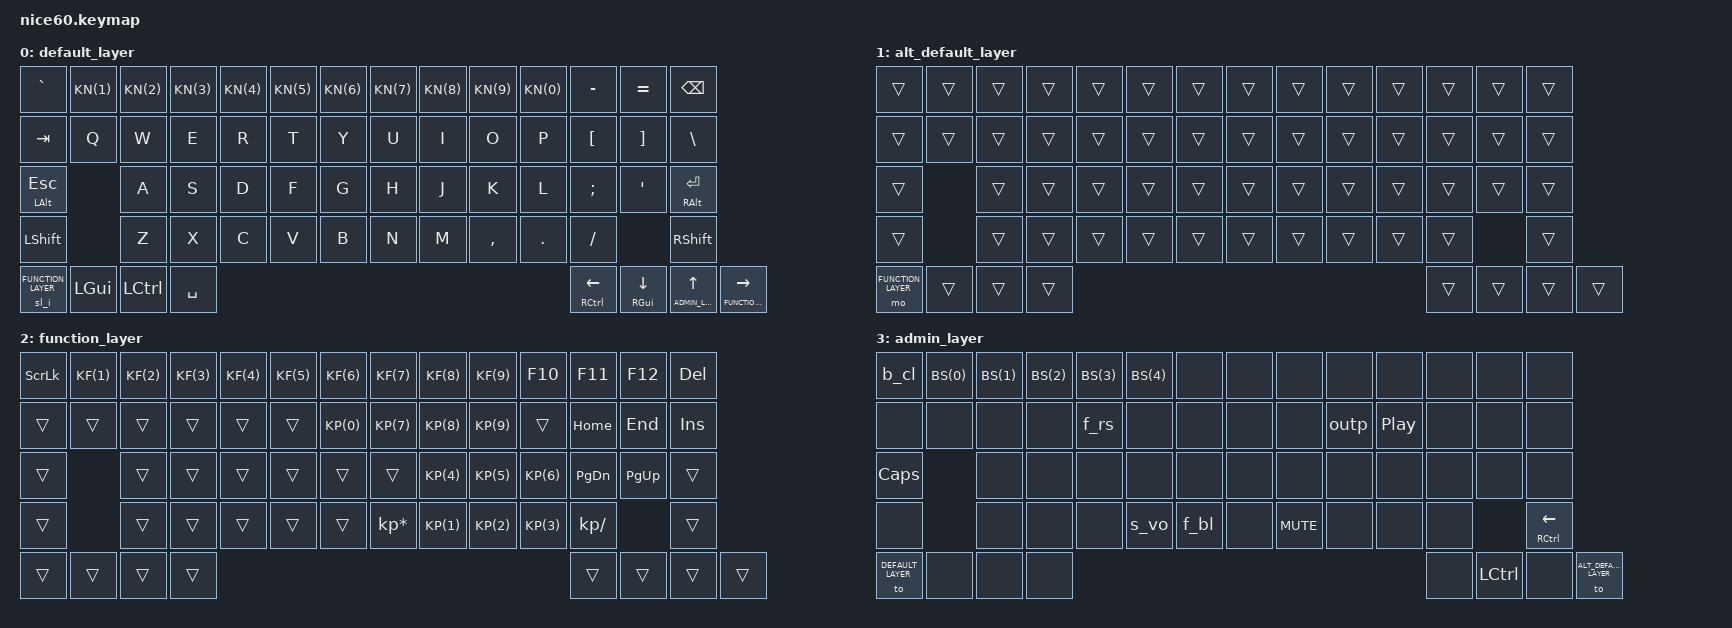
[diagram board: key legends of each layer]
/*
 * Copyright (c) 2022 Konstantin Lepa
 *
 * SPDX-License-Identifier: MIT
 */

#include <behaviors.dtsi>
#include <dt-bindings/zmk/keys.h>
#include <dt-bindings/zmk/rgb.h>
#include <dt-bindings/zmk/bt.h>
#include <dt-bindings/zmk/outputs.h>
#include <dt-bindings/zmk/reset.h>
#include <dt-bindings/zmk/ext_power.h>

#define DEFAULT_LAYER     0
#define ALT_DEFAULT_LAYER 1
#define FUNCTION_LAYER    2
#define ADMIN_LAYER       3

#define K_TRN &trans

//
// DEFINITIONS: DEFAULT LAYER
//

// Row 1
#define K_GRV &kp GRAVE
#define KN(X) &kp N ## X
#define K_MIN &kp MINUS
#define K_EQU &kp EQUAL
#define K_BSP &kp BSPC

// Row 2
#define K_TAB &kp TAB
#define K_LBT &kp LBKT
#define K_RBT &kp RBKT
#define K_BSL &kp BSLH

// Row 3
#define K_ESC &mt LALT ESC
#define K_SCL &kp SEMI
#define K_SQT &kp SQT
#define K_RET &mt RALT RET

// Row 4
#define K_LST &kp LSHFT
#define K_COM &kp COMMA
#define K_DOT &kp DOT
#define K_FSL &kp FSLH
#define K_RST &kp RSHFT

// Row 5
#define K_LFN &sl_i FUNCTION_LAYER
#define K_LCL &kp LCTRL
#define K_LGU &kp LGUI
#define K_SPS &kp SPACE
#define K_RGU &mt RGUI DOWN
#define K_RCL &mt RCTRL LEFT
#define K_ADM &lt ADMIN_LAYER UP
#define K_RFN &lt FUNCTION_LAYER RIGHT


//////
// DEFINITIONS: ALTERNATE DEFAULT LAYER
//

// Row 5
#define K_AFN &mo FUNCTION_LAYER


//////
// DEFINTIONS: FUNCTION LAYER
//

// Row 1
#define K_SLK &kp SLCK
#define KF(X) &kp F ## X
#define K_F10 &kp F10
#define K_F11 &kp F11
#define K_F12 &kp F12
#define K_DEL &kp DEL

// Row 2
#define KP(X) &kp KP_N ## X
#define K_HOM &kp HOME
#define K_END &kp END
#define K_INS &kp INS

// Row 3
#define K_PGD &kp PG_DN
#define K_PGU &kp PG_UP

// Row 4
#define KP_AS &kp KP_ASTERISK
#define KP_SL &kp KP_SLASH


//////
// DEFINITIONS: ADMIN LAYER
//

// Row 1
#define BS(X) &bt BT_SEL X

// Row 2
#define M_PLP &kp C_PP

// Row 3
#define K_CAP &kp CAPS

// Row 4
#define S_MUT &kp K_MUTE

// Row 5
#define K_DFL &to DEFAULT_LAYER
#define K_ADF &to ALT_DEFAULT_LAYER


//////
// CONFIGURATION
//

&mt {
	quick-tap-ms = <200>;
};

&lt {
	quick-tap-ms = <200>;
};

/ {
	behaviors {
		sl_i: behavior_sticky_layer {
			compatible = "zmk,behavior-sticky-key";
			label = "STICKY_LAYER_IMPROVED";
			#binding-cells = <1>;
			release-after-ms = <3000>;
			bindings = <&mo>;
			quick-release;
			ignore-modifiers;
		};

		s_vo: snd_volume {
			compatible = "zmk,behavior-mod-morph";
			label = "SND_VOLUME";
			#binding-cells = <0>;
			bindings = <&kp C_VOL_UP>, <&kp C_VOL_DN>;
			mods = <(MOD_RCTL)>;
		};

		f_bl: firmware {
			compatible = "zmk,behavior-mod-morph";
			label = "FIRMWARE";
			#binding-cells = <0>;
			bindings = <&none>, <&bootloader>;
			mods = <(MOD_LCTL)>;
		};
		
		f_rs: firmware {
			compatible = "zmk,behavior-mod-morph";
			label = "FIRMWARE";
			#binding-cells = <0>;
			bindings = <&none>, <&reset>;
			mods = <(MOD_LCTL)>;
		};
		
		outp: output {
			compatible = "zmk,behavior-mod-morph";
			label = "OUTPUT";
			#binding-cells = <0>;
			bindings = <&out OUT_BLE>, <&out OUT_USB>;
			mods = <(MOD_RCTL)>;
		};
		
		b_cl: bt_clear {
			compatible = "zmk,behavior-mod-morph";
			label = "BLE_CLEAR";
			#binding-cells = <0>;
			bindings = <&none>, <&bt BT_CLR>;
			mods = <(MOD_LCTL)>;
		};
	};

	keymap {
		compatible = "zmk,keymap";
		
		default_layer {
			bindings = <
				/* Row 1 */   K_GRV  KN(1)  KN(2)  KN(3)  KN(4)  KN(5)  KN(6)  KN(7)  KN(8)  KN(9)  KN(0)  K_MIN  K_EQU         K_BSP
				/* Row 2 */   K_TAB         &kp Q  &kp W  &kp E  &kp R  &kp T  &kp Y  &kp U  &kp I  &kp O  &kp P  K_LBT  K_RBT  K_BSL
				/* Row 3 */   K_ESC         &kp A  &kp S  &kp D  &kp F  &kp G  &kp H  &kp J  &kp K  &kp L  K_SCL  K_SQT         K_RET
				/* Row 4 */   K_LST         &kp Z  &kp X  &kp C  &kp V  &kp B  &kp N  &kp M  K_COM  K_DOT  K_FSL                K_RST
				/* Row 5 */   K_LFN  K_LGU  K_LCL                       K_SPS                              K_RCL  K_RGU  K_ADM  K_RFN
			>;
		};

		alt_default_layer {
			bindings = <
				/* Row 1 */   K_TRN  K_TRN  K_TRN  K_TRN  K_TRN  K_TRN  K_TRN  K_TRN  K_TRN  K_TRN  K_TRN  K_TRN  K_TRN         K_TRN
				/* Row 2 */   K_TRN         K_TRN  K_TRN  K_TRN  K_TRN  K_TRN  K_TRN  K_TRN  K_TRN  K_TRN  K_TRN  K_TRN  K_TRN  K_TRN
				/* Row 3 */   K_TRN         K_TRN  K_TRN  K_TRN  K_TRN  K_TRN  K_TRN  K_TRN  K_TRN  K_TRN  K_TRN  K_TRN         K_TRN
				/* Row 4 */   K_TRN         K_TRN  K_TRN  K_TRN  K_TRN  K_TRN  K_TRN  K_TRN  K_TRN  K_TRN  K_TRN                K_TRN
				/* Row 5 */   K_AFN  K_TRN  K_TRN                       K_TRN                              K_TRN  K_TRN  K_TRN  K_TRN
			>;
		};

		function_layer {
			bindings = <
				/* Row 1 */   K_SLK  KF(1)  KF(2)  KF(3)  KF(4)  KF(5)  KF(6)  KF(7)  KF(8)  KF(9)  K_F10  K_F11  K_F12         K_DEL
				/* Row 2 */   K_TRN         K_TRN  K_TRN  K_TRN  K_TRN  K_TRN  KP(0)  KP(7)  KP(8)  KP(9)  K_TRN  K_HOM  K_END  K_INS
				/* Row 3 */   K_TRN         K_TRN  K_TRN  K_TRN  K_TRN  K_TRN  K_TRN  KP(4)  KP(5)  KP(6)  K_PGD  K_PGU         K_TRN
				/* Row 4 */   K_TRN         K_TRN  K_TRN  K_TRN  K_TRN  K_TRN  KP_AS  KP(1)  KP(2)  KP(3)  KP_SL                K_TRN
				/* Row 5 */   K_TRN  K_TRN  K_TRN                       K_TRN                              K_TRN  K_TRN  K_TRN  K_TRN
			>;
		};

		admin_layer {
			bindings = <
				/* Row 1 */   &b_cl  BS(0)  BS(1)  BS(2)  BS(3)  BS(4)  &none  &none  &none  &none  &none  &none  &none         &none
				/* Row 2 */   &none         &none  &none  &none  &f_rs  &none  &none  &none  &none  &outp  M_PLP  &none  &none  &none
				/* Row 3 */   K_CAP         &none  &none  &none  &none  &none  &none  &none  &none  &none  &none  &none         &none
				/* Row 4 */   &none         &none  &none  &none  &s_vo  &f_bl  &none  S_MUT  &none  &none  &none                K_RCL
				/* Row 5 */   K_DFL  &none  &none                       &none                              &none  K_LCL  &none  K_ADF
			>;
		};
	};
};
